# NAVSS0_UDMASS_INTA_0_UDMASS_INTA0_CFG_UNMAP register map
Vendor: Texas Instruments
Peripheral module from a debugger description file (folder J721S2).
Registers are 64-bit, read-write, reset 0xFFFF unless marked. A register's access mark holds for its fields unless they carry their own. Offsets are as the file gives them; lines under a group give offsets from that group; [hi:lo] are bit positions; {n}, {i} and the like mark numbered series; 'fields as' and 'values as' point back to an identical list; <NAME> marks a mode.

## NAVSS0_UDMASS_INTA_0_UDMASS_INTA0_CFG_UNMAP
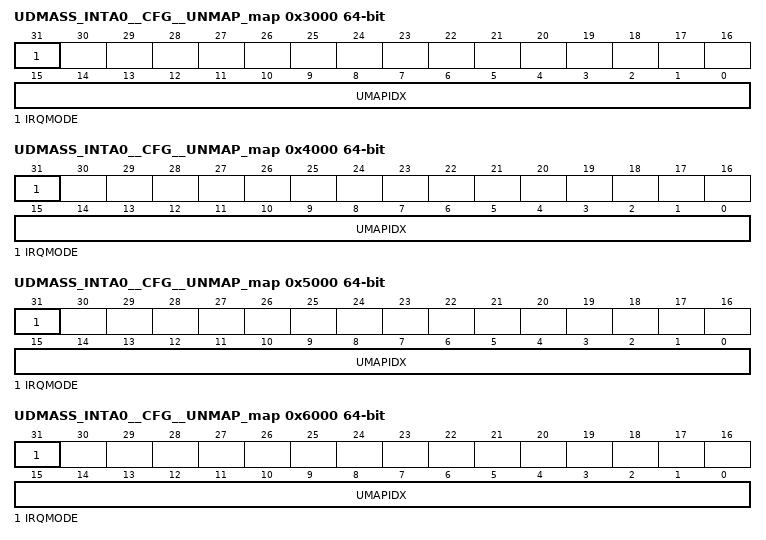
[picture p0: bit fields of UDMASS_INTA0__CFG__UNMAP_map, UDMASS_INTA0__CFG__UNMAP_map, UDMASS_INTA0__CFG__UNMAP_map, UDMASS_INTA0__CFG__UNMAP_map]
0x3000 UDMASS_INTA0__CFG__UNMAP_map — The Global Event Mapping register controls the egress global event index for this unmapped event. This register may also be optionally used to directly set an interrupt status bit by using the irqmode flag.
  [31] IRQMODE — IRQ Mode Flag. When set, this register act like a mapper with bitnum in 5:0 and regnum in 14:6.
  [15:0] UMAPIDX — Global event index. This field specifies the index of the outgoing global event. Set to 0xFFFF to disable.
0x4000 UDMASS_INTA0__CFG__UNMAP_map — The Global Event Mapping register controls the egress global event index for this unmapped event. This register may also be optionally used to directly set an interrupt status bit by using the irqmode flag.
  fields as UDMASS_INTA0__CFG__UNMAP_map
0x5000 UDMASS_INTA0__CFG__UNMAP_map — The Global Event Mapping register controls the egress global event index for this unmapped event. This register may also be optionally used to directly set an interrupt status bit by using the irqmode flag.
  fields as UDMASS_INTA0__CFG__UNMAP_map
0x6000 UDMASS_INTA0__CFG__UNMAP_map — The Global Event Mapping register controls the egress global event index for this unmapped event. This register may also be optionally used to directly set an interrupt status bit by using the irqmode flag.
  fields as UDMASS_INTA0__CFG__UNMAP_map
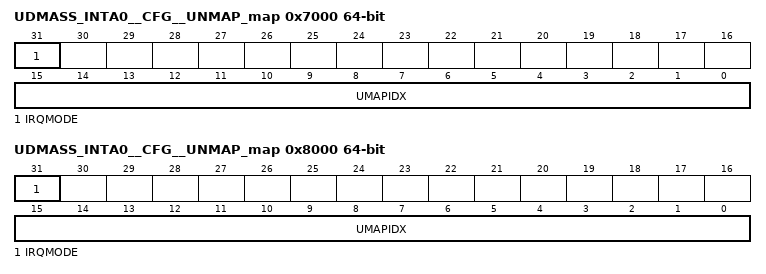
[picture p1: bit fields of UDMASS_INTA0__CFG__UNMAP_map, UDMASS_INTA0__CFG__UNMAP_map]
0x7000 UDMASS_INTA0__CFG__UNMAP_map — The Global Event Mapping register controls the egress global event index for this unmapped event. This register may also be optionally used to directly set an interrupt status bit by using the irqmode flag.
  fields as UDMASS_INTA0__CFG__UNMAP_map
0x8000 UDMASS_INTA0__CFG__UNMAP_map — The Global Event Mapping register controls the egress global event index for this unmapped event. This register may also be optionally used to directly set an interrupt status bit by using the irqmode flag.
  fields as UDMASS_INTA0__CFG__UNMAP_map
